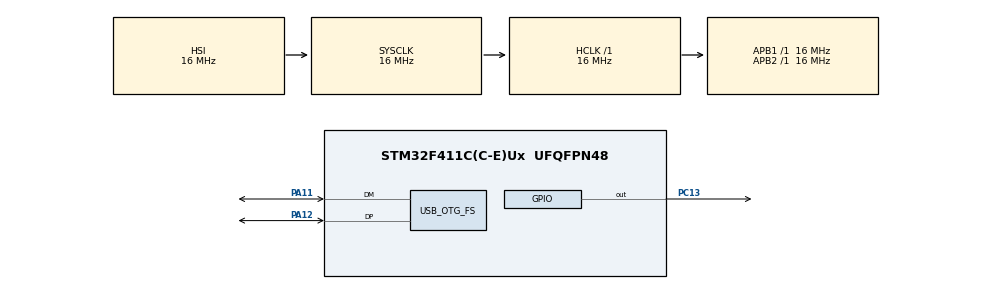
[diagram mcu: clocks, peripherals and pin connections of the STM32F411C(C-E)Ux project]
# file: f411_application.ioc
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FREERTOS.Tasks01=defaultTask,24,128,StartDefaultTask,Default,NULL,Dynamic,NULL,NULL
FREERTOS.configUSE_NEWLIB_REENTRANT=1
Mcu.Family=STM32F4
Mcu.Name=STM32F411C(C-E)Ux
Mcu.Package=UFQFPN48
NVIC.OTG_FS_IRQn=true\:5\:0\:false\:false\:true\:true\:true\:true
NVIC.PriorityGroup=NVIC_PRIORITYGROUP_4
NVIC.TIM1_UP_TIM10_IRQn=true\:15\:0\:false\:false\:true\:false\:false\:true
NVIC.TimeBase=TIM1_UP_TIM10_IRQn
NVIC.TimeBaseIP=TIM1
PA11.Mode=Device_Only
PA11.Signal=USB_OTG_FS_DM
PA12.Mode=Device_Only
PA12.Signal=USB_OTG_FS_DP
PC13-ANTI_TAMP.PinState=GPIO_PIN_SET
PC13-ANTI_TAMP.Signal=GPIO_Output
PH0\ -\ OSC_IN.Mode=HSE-External-Oscillator
PH0\ -\ OSC_IN.Signal=RCC_OSC_IN
PH1\ -\ OSC_OUT.Mode=HSE-External-Oscillator
PH1\ -\ OSC_OUT.Signal=RCC_OSC_OUT
ProjectManager.HeapSize=0x200
ProjectManager.StackSize=0x400
ProjectManager.TargetToolchain=STM32CubeIDE
RCC.48MHZClocksFreq_Value=48000000
RCC.AHBFreq_Value=16000000
RCC.APB1Freq_Value=16000000
RCC.APB2Freq_Value=16000000
RCC.CortexFreq_Value=16000000
RCC.HSE_VALUE=25000000
RCC.HSI_VALUE=16000000
RCC.LSE_VALUE=32768
RCC.PLLM=15
RCC.PLLN=144
RCC.PLLQ=5
RCC.SYSCLKFreq_VALUE=16000000
RCC.VCOOutputFreq_Value=240000000
USB_DEVICE.CLASS_NAME_FS=CDC
USB_DEVICE.PID_CDC_FS=22337
USB_DEVICE.PRODUCT_STRING_CDC_FS=Janoko Com
USB_DEVICE.VirtualMode=Cdc
USB_DEVICE.VirtualModeFS=Cdc_FS
USB_OTG_FS.Sof_enable=ENABLE
USB_OTG_FS.VirtualMode=Device_Only
VP_FREERTOS_VS_CMSIS_V2.Mode=CMSIS_V2
VP_SYS_VS_tim1.Mode=TIM1
VP_USB_DEVICE_VS_USB_DEVICE_CDC_FS.Mode=CDC_FS
board=custom

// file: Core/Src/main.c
/* USER CODE BEGIN Header */
/**
  ******************************************************************************
  * @file           : main.c
  * @brief          : Main program body
  ******************************************************************************
  * @attention
  *
  * <h2><center>&copy; Copyright (c) 2021 STMicroelectronics.
  * All rights reserved.</center></h2>
  *
  * This software component is licensed by ST under BSD 3-Clause license,
  * the "License"; You may not use this file except in compliance with the
  * License. You may obtain a copy of the License at:
  *                        opensource.org/licenses/BSD-3-Clause
  *
  ******************************************************************************
  */
/* USER CODE END Header */
#include "main.h"
#include "cmsis_os.h"
#include "usb_device.h"
#include "usb_device.h"

/* USER CODE BEGIN Includes */
#include "usbd_cdc_if.h"
#include "firmware.h"
#include "led_user.h"
#include "debugger.h"
#include <stdio.h>

/* USER CODE END Includes */

/* Definitions for defaultTask */
osThreadId_t defaultTaskHandle;
const osThreadAttr_t defaultTask_attributes = {
  .name = "defaultTask",
  .stack_size = 128 * 4,
  .priority = (osPriority_t) osPriorityNormal,
};

void SystemClock_Config(void);
static void MX_GPIO_Init(void);
void StartDefaultTask(void *argument);

/* USER CODE BEGIN 0 */
void CDC_OnRecieveData(uint8_t* Buf, uint32_t Len)
{
  switch (Buf[0]) {
  case '!':
    Firmware_Detail.isUpdate = 1;
    Firmware_SaveDetail(&Firmware_Detail);
    NVIC_SystemReset();
    break;
  case '@':
    printf("Bep");
  }
  if(Len && Buf[0] == 67){
//    vTaskEndScheduler();

  }
}
/* USER CODE END 0 */

int main(void)
{

  /* MCU Configuration--------------------------------------------------------*/

  /* Reset of all peripherals, Initializes the Flash interface and the Systick. */
  HAL_Init();

  /* Configure the system clock */
  SystemClock_Config();

  /* Initialize all configured peripherals */
  MX_GPIO_Init();
  /* USER CODE BEGIN 2 */

  Firmware_SetVersion(&Firmware_Detail, 1, 0, 0);
  Firmware_SaveDetail(&Firmware_Detail);
  /* USER CODE END 2 */

  /* Init scheduler */
  osKernelInitialize();

  /* Create the thread(s) */
  /* creation of defaultTask */
  defaultTaskHandle = osThreadNew(StartDefaultTask, NULL, &defaultTask_attributes);

  /* Start scheduler */
  osKernelStart();

  /* We should never get here as control is now taken by the scheduler */
  /* Infinite loop */
  while (1)
  {

  }
}

void SystemClock_Config(void)
{
  RCC_OscInitTypeDef RCC_OscInitStruct = {0};
  RCC_ClkInitTypeDef RCC_ClkInitStruct = {0};

  /** Configure the main internal regulator output voltage
  */
  __HAL_RCC_PWR_CLK_ENABLE();
  __HAL_PWR_VOLTAGESCALING_CONFIG(PWR_REGULATOR_VOLTAGE_SCALE1);
  /** Initializes the RCC Oscillators according to the specified parameters
  * in the RCC_OscInitTypeDef structure.
  */
  RCC_OscInitStruct.OscillatorType = RCC_OSCILLATORTYPE_HSI|RCC_OSCILLATORTYPE_HSE;
  RCC_OscInitStruct.HSEState = RCC_HSE_ON;
  RCC_OscInitStruct.HSIState = RCC_HSI_ON;
  RCC_OscInitStruct.HSICalibrationValue = RCC_HSICALIBRATION_DEFAULT;
  RCC_OscInitStruct.PLL.PLLState = RCC_PLL_ON;
  RCC_OscInitStruct.PLL.PLLSource = RCC_PLLSOURCE_HSE;
  RCC_OscInitStruct.PLL.PLLM = 15;
  RCC_OscInitStruct.PLL.PLLN = 144;
  RCC_OscInitStruct.PLL.PLLP = RCC_PLLP_DIV2;
  RCC_OscInitStruct.PLL.PLLQ = 5;
  if (HAL_RCC_OscConfig(&RCC_OscInitStruct) != HAL_OK)
  {
    Error_Handler();
  }
  /** Initializes the CPU, AHB and APB buses clocks
  */
  RCC_ClkInitStruct.ClockType = RCC_CLOCKTYPE_HCLK|RCC_CLOCKTYPE_SYSCLK
                              |RCC_CLOCKTYPE_PCLK1|RCC_CLOCKTYPE_PCLK2;
  RCC_ClkInitStruct.SYSCLKSource = RCC_SYSCLKSOURCE_HSI;
  RCC_ClkInitStruct.AHBCLKDivider = RCC_SYSCLK_DIV1;
  RCC_ClkInitStruct.APB1CLKDivider = RCC_HCLK_DIV1;
  RCC_ClkInitStruct.APB2CLKDivider = RCC_HCLK_DIV1;

  if (HAL_RCC_ClockConfig(&RCC_ClkInitStruct, FLASH_LATENCY_0) != HAL_OK)
  {
    Error_Handler();
  }
}

static void MX_GPIO_Init(void)
{
  GPIO_InitTypeDef GPIO_InitStruct = {0};

  /* GPIO Ports Clock Enable */
  __HAL_RCC_GPIOC_CLK_ENABLE();
  __HAL_RCC_GPIOH_CLK_ENABLE();
  __HAL_RCC_GPIOA_CLK_ENABLE();

  /*Configure GPIO pin Output Level */
  HAL_GPIO_WritePin(GPIOC, GPIO_PIN_13, GPIO_PIN_SET);

  /*Configure GPIO pin : PC13 */
  GPIO_InitStruct.Pin = GPIO_PIN_13;
  GPIO_InitStruct.Mode = GPIO_MODE_OUTPUT_PP;
  GPIO_InitStruct.Pull = GPIO_NOPULL;
  GPIO_InitStruct.Speed = GPIO_SPEED_FREQ_LOW;
  HAL_GPIO_Init(GPIOC, &GPIO_InitStruct);

}

void StartDefaultTask(void *argument)
{
  /* init code for USB_DEVICE */
  MX_USB_DEVICE_Init();
  /* USER CODE BEGIN 5 */
  bepBlink(1, 3000, 100);
  DBG_Print("Start");

  /* Infinite loop */
  for(;;)
  {
    DBG_Print("Bep");
    bepBlink(2, 100, 100);
    osDelay(4000);
  }
  /* USER CODE END 5 */
}

void HAL_TIM_PeriodElapsedCallback(TIM_HandleTypeDef *htim)
{
  if (htim->Instance == TIM1) {
    HAL_IncTick();
  }
}

void Error_Handler(void)
{
  __disable_irq();
  while (1)
  {
  }
}

/************************ (C) COPYRIGHT STMicroelectronics *****END OF FILE****/
